VERSION ""

NS_ :

BS_:

BU_: ECM Racecapture BCM EHPAS ABS SteeringWheel PMU

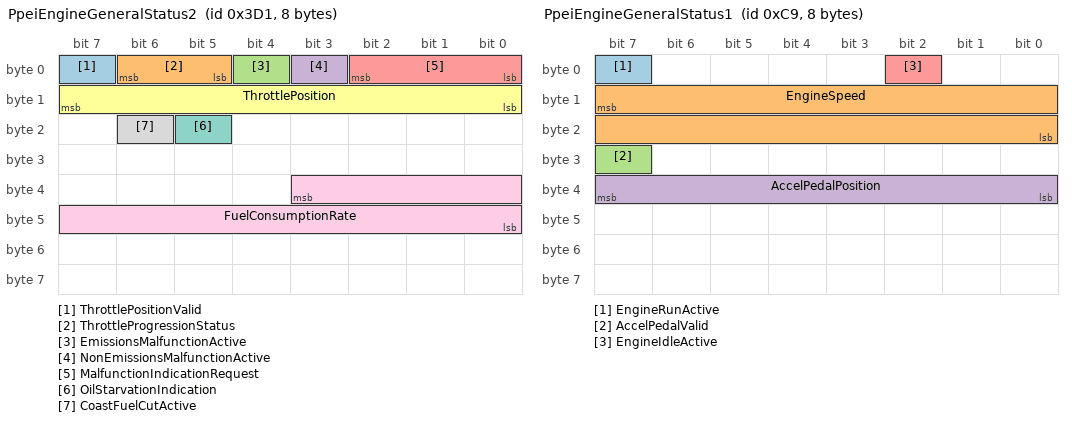
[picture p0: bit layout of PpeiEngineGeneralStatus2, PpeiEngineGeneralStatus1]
BO_ 977 PpeiEngineGeneralStatus2: 8 ECM
 SG_ ThrottlePositionValid : 7|1@1+ (1,0) [0|0] "flag" Vector__XXX
 SG_ ThrottleProgressionStatus : 6|2@0+ (1,0) [0|0] ""  BCM
 SG_ EmissionsMalfunctionActive : 4|1@1+ (1,0) [0|0] "flag" Vector__XXX
 SG_ NonEmissionsMalfunctionActive : 3|1@1+ (1,0) [0|0] "flag" Vector__XXX
 SG_ MalfunctionIndicationRequest : 2|3@0+ (1,0) [0|0] "" Vector__XXX
 SG_ ThrottlePosition : 15|8@0+ (0.39215686274,0) [0|100] "%" Vector__XXX
 SG_ OilStarvationIndication : 21|1@1+ (1,0) [0|0] "flag"  Racecapture
 SG_ CoastFuelCutActive : 22|1@1+ (1,0) [0|0] "flag" Vector__XXX
 SG_ FuelConsumptionRate : 35|12@0+ (0.025,0) [0|102.375] "L/h"  Racecapture

BO_ 201 PpeiEngineGeneralStatus1: 8 ECM
 SG_ EngineRunActive : 7|1@0+ (1,0) [0|0] "flag"  Racecapture,BCM
 SG_ EngineSpeed : 15|16@0+ (0.25,0) [0|16383.8] "rpm"  Racecapture,BCM
 SG_ AccelPedalValid : 31|1@0+ (1,0) [0|0] "flag" Vector__XXX
 SG_ AccelPedalPosition : 39|8@0+ (0.39215686274,0) [0|100] "%"  BCM,Racecapture
 SG_ EngineIdleActive : 2|1@0+ (1,0) [0|0] "" Vector__XXX

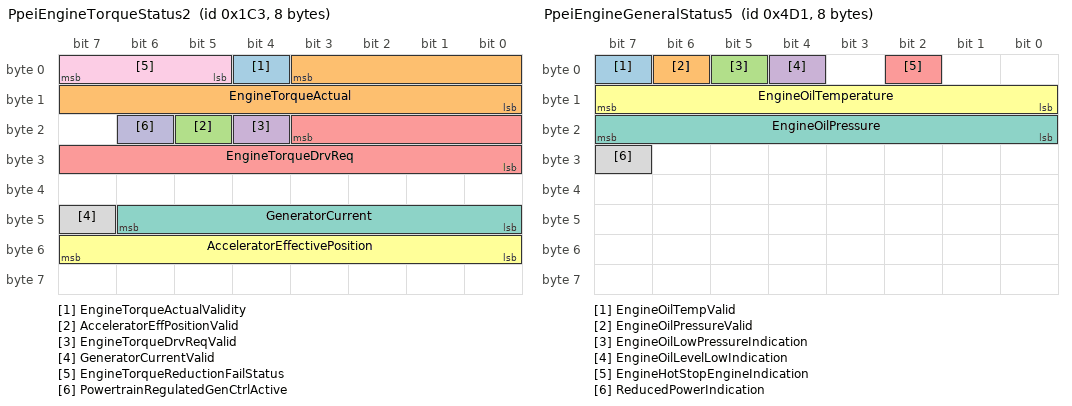
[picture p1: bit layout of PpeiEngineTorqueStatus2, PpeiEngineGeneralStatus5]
BO_ 451 PpeiEngineTorqueStatus2: 8 ECM
 SG_ EngineTorqueActualValidity : 4|1@0+ (1,0) [0|0] "flag" Vector__XXX
 SG_ EngineTorqueActual : 3|12@0+ (0.5,-848) [-848|1199.5] "Nm"  Racecapture
 SG_ AcceleratorEffPositionValid : 21|1@0+ (1,0) [0|0] "flag" Vector__XXX
 SG_ EngineTorqueDrvReqValid : 20|1@0+ (1,0) [0|0] "flag" Vector__XXX
 SG_ EngineTorqueDrvReq : 19|12@0+ (0.5,-848) [-848|1199.5] "Nm" Vector__XXX
 SG_ AcceleratorEffectivePosition : 55|8@0+ (0.39215686274,0) [0|100] "%" Vector__XXX
 SG_ GeneratorCurrent : 46|7@0+ (1,0) [0|127] "A" Vector__XXX
 SG_ GeneratorCurrentValid : 47|1@0+ (1,0) [0|0] "flag" Vector__XXX
 SG_ EngineTorqueReductionFailStatus : 7|3@0+ (1,0) [0|0] "enum" Vector__XXX
 SG_ PowertrainRegulatedGenCtrlActive : 22|1@0+ (1,0) [0|0] "flag" Vector__XXX

BO_ 1233 PpeiEngineGeneralStatus5: 8 ECM
 SG_ EngineOilTempValid : 7|1@1+ (1,0) [0|0] "flag" Vector__XXX
 SG_ EngineOilPressureValid : 6|1@1+ (1,0) [0|0] "flag" Vector__XXX
 SG_ EngineOilLowPressureIndication : 5|1@1+ (1,0) [0|0] "flag"  Racecapture
 SG_ EngineOilLevelLowIndication : 4|1@1+ (1,0) [0|0] "flag"  Racecapture
 SG_ EngineHotStopEngineIndication : 2|1@1+ (1,0) [0|0] "flag" Vector__XXX
 SG_ EngineOilTemperature : 15|8@0+ (1,-40) [-40|215] "deg C"  Racecapture
 SG_ EngineOilPressure : 23|8@0+ (4,0) [0|1020] "kPa"  Racecapture
 SG_ ReducedPowerIndication : 31|1@1+ (1,0) [0|0] "flag" Vector__XXX

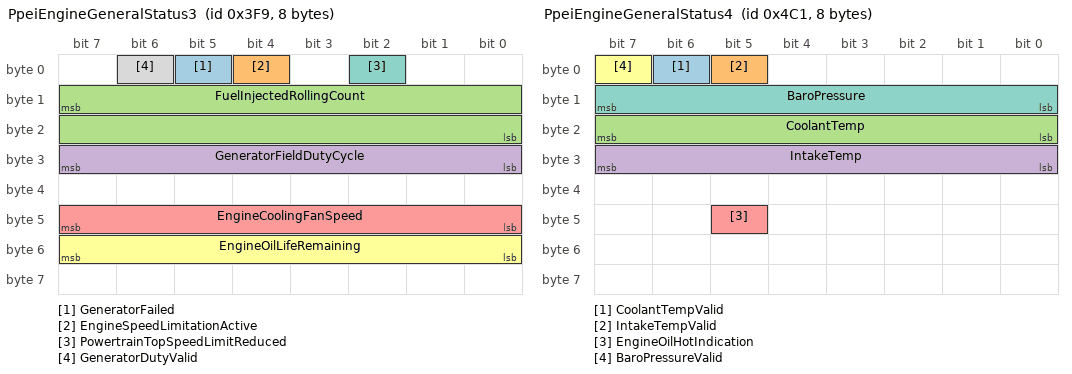
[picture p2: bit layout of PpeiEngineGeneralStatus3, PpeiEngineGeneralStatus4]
BO_ 1017 PpeiEngineGeneralStatus3: 8 ECM
 SG_ GeneratorFailed : 5|1@1+ (1,0) [0|0] "flag"  Racecapture
 SG_ EngineSpeedLimitationActive : 4|1@1+ (1,0) [0|0] "flag"  Racecapture
 SG_ FuelInjectedRollingCount : 15|16@0+ (3.0517578125e-05,0) [0|2] "liter"  BCM
 SG_ GeneratorFieldDutyCycle : 31|8@0+ (0.39215686274,0) [0|100] "%" Vector__XXX
 SG_ EngineCoolingFanSpeed : 47|8@0+ (0.39215686274,0) [0|100] "%" Vector__XXX
 SG_ EngineOilLifeRemaining : 55|8@0+ (0.39215686274,0) [0|100] "%" Vector__XXX
 SG_ PowertrainTopSpeedLimitReduced : 2|1@0+ (1,0) [0|0] "flag" Vector__XXX
 SG_ GeneratorDutyValid : 6|1@0+ (1,0) [0|0] "flag" Vector__XXX

BO_ 1019 PpeiEngineFuelStatus: 8 ECM
 SG_ EngineFuelControlState : 1|2@0+ (1,0) [0|0] ""  Racecapture
 SG_ FuelAlcoholComposition : 15|8@0+ (0.39215686274,0) [0|100] "%"  Racecapture

BO_ 1217 PpeiEngineGeneralStatus4: 8 ECM
 SG_ CoolantTempValid : 6|1@1+ (1,0) [0|0] "flag" Vector__XXX
 SG_ IntakeTempValid : 5|1@1+ (1,0) [0|0] "flag" Vector__XXX
 SG_ CoolantTemp : 23|8@0+ (1,-40) [-40|215] "deg C"  Racecapture
 SG_ IntakeTemp : 31|8@0+ (1,-40) [-40|215] "deg C"  Racecapture
 SG_ EngineOilHotIndication : 45|1@1+ (1,0) [0|0] "flag"  Racecapture
 SG_ BaroPressureValid : 7|1@1+ (1,0) [0|0] "flag" Vector__XXX
 SG_ BaroPressure : 15|8@0+ (0.5,0) [0|127.5] "kPa" Vector__XXX

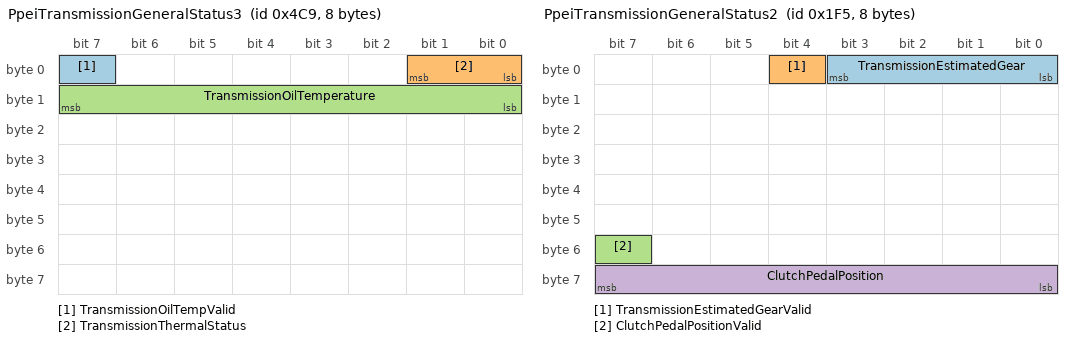
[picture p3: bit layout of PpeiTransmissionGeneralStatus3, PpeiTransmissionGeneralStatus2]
BO_ 1225 PpeiTransmissionGeneralStatus3: 8 ECM
 SG_ TransmissionOilTempValid : 7|1@1+ (1,0) [0|0] "flag" Vector__XXX
 SG_ TransmissionThermalStatus : 1|2@0+ (1,0) [0|0] "" Vector__XXX
 SG_ TransmissionOilTemperature : 15|8@0+ (1,-40) [-40|215] "deg C"  Racecapture

BO_ 495 PpeiFuelSystemRequest2: 8 ECM
 SG_ MassAirFlow : 7|16@0+ (0.01,0) [0|655.35] "g/s"  Racecapture

BO_ 501 PpeiTransmissionGeneralStatus2: 8 ECM
 SG_ TransmissionEstimatedGear : 0|4@1+ (1,0) [0|0] ""  Racecapture
 SG_ TransmissionEstimatedGearValid : 4|1@1+ (1,0) [0|0] "flag" Vector__XXX
 SG_ ClutchPedalPositionValid : 55|1@1+ (1,0) [0|0] "flag" Vector__XXX
 SG_ ClutchPedalPosition : 63|8@0+ (0.39215686274,0) [0|100] "%"  Racecapture

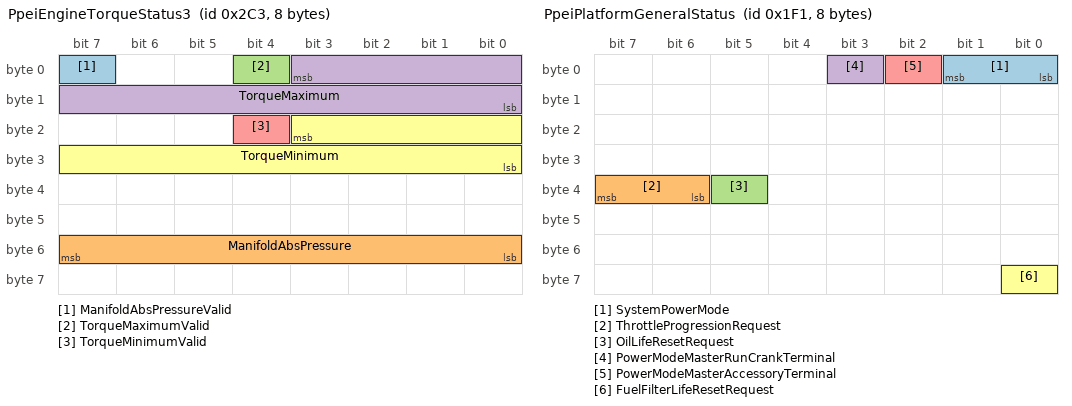
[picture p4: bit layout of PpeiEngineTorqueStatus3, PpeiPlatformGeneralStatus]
BO_ 707 PpeiEngineTorqueStatus3: 8 ECM
 SG_ ManifoldAbsPressureValid : 7|1@1+ (1,0) [0|0] "flag" Vector__XXX
 SG_ ManifoldAbsPressure : 55|8@0+ (0.5,0) [0|127.5] "kPa"  Racecapture
 SG_ TorqueMaximumValid : 4|1@1+ (1,0) [0|0] "flag" Vector__XXX
 SG_ TorqueMaximum : 3|12@0+ (0.5,-848) [-848|1199.5] "Nm" Vector__XXX
 SG_ TorqueMinimumValid : 20|1@0+ (1,0) [0|0] "flag" Vector__XXX
 SG_ TorqueMinimum : 19|12@0+ (0.5,-848) [-848|1199.5] "Nm" Vector__XXX

BO_ 1001 PpeiVehicleSpeedAndDistance: 8 ECM
 SG_ VehicleSpeedDrivenValid : 7|1@1+ (1,0) [0|0] "" Vector__XXX
 SG_ VehicleSpeedDriven : 6|15@0+ (0.015625,0) [0|511.46] "km/h"  Racecapture

BO_ 497 PpeiPlatformGeneralStatus: 8 BCM
 SG_ SystemPowerMode : 1|2@0+ (1,0) [0|0] ""  ECM
 SG_ ThrottleProgressionRequest : 39|2@0+ (1,0) [0|0] ""  ECM
 SG_ OilLifeResetRequest : 37|1@0+ (1,0) [0|0] ""  ECM
 SG_ PowerModeMasterRunCrankTerminal : 3|1@0+ (1,0) [0|0] "" Vector__XXX
 SG_ PowerModeMasterAccessoryTerminal : 2|1@0+ (1,0) [0|0] "" Vector__XXX
 SG_ FuelFilterLifeResetRequest : 56|1@0+ (1,0) [0|0] "" Vector__XXX

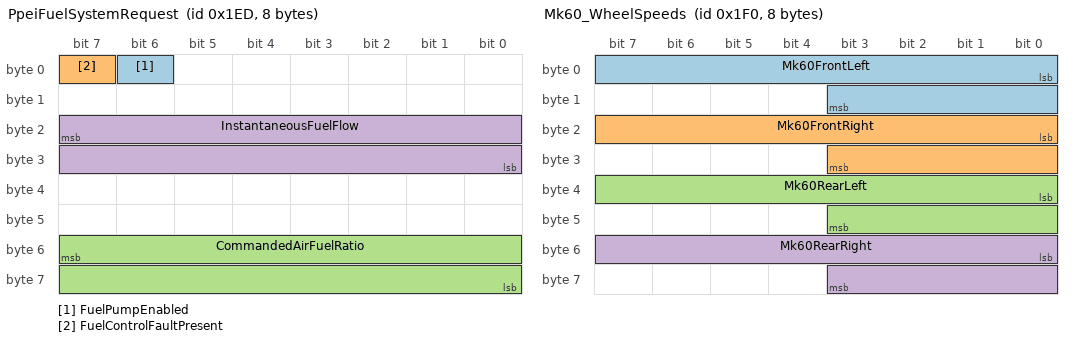
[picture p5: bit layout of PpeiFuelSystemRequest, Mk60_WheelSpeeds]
BO_ 493 PpeiFuelSystemRequest: 8 ECM
 SG_ FuelPumpEnabled : 6|1@1+ (1,0) [0|0] "flag"  BCM
 SG_ FuelControlFaultPresent : 7|1@1+ (1,0) [0|0] "flag" Vector__XXX
 SG_ CommandedAirFuelRatio : 55|16@0+ (0.00048828125,0) [0|32] "ratio"  ECM
 SG_ InstantaneousFuelFlow : 23|16@0+ (0.0009765625,0) [0|64] "g/s"  ECM

BO_ 2598373676 VolvoPowerSteeringIgnitionOn: 8 BCM
 SG_ EhpasIgnitionRollCount : 8|8@1+ (1,0) [0|0] ""  EHPAS

BO_ 2602565634 VolvoPowerSteeringAlive: 8 EHPAS
 SG_ VolvoEhpasAlive : 0|64@1+ (1,0) [0|0] "" Vector__XXX

BO_ 2182103350 VolvoPowerSteeringSpeed: 8 BCM
 SG_ EhpasVehicleSpeed : 55|16@0+ (0.01,0) [0|0] "km/h"  EHPAS

BO_ 496 Mk60_WheelSpeeds: 8 ABS
 SG_ Mk60FrontLeft : 0|12@1+ (0.03125,-0.5) [0|0] "km/h" Vector__XXX
 SG_ Mk60FrontRight : 16|12@1+ (0.03125,-0.5) [0|0] "km/h" Vector__XXX
 SG_ Mk60RearLeft : 32|12@1+ (0.03125,-0.5) [0|0] "km/h" Vector__XXX
 SG_ Mk60RearRight : 48|12@1+ (0.03125,-0.5) [0|0] "km/h" Vector__XXX

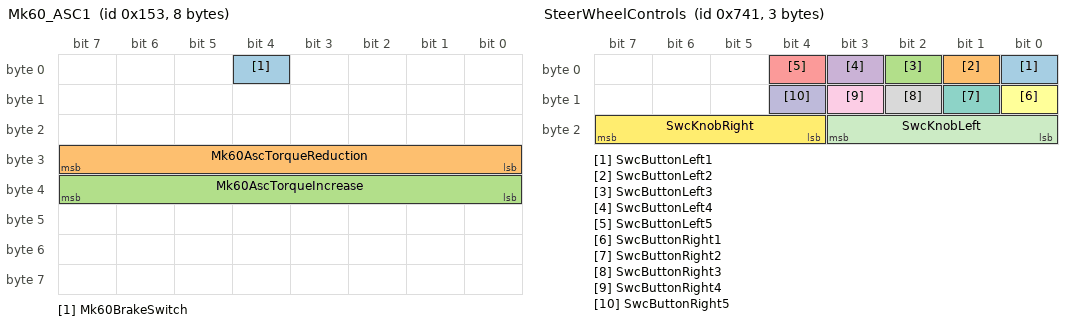
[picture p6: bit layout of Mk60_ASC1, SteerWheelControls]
BO_ 339 Mk60_ASC1: 8 ABS
 SG_ Mk60BrakeSwitch : 4|1@1+ (1,0) [0|0] "flag"  BCM
 SG_ Mk60AscTorqueReduction : 24|8@1+ (0.390625,0) [0|100] "%"  BCM
 SG_ Mk60AscTorqueIncrease : 32|8@1+ (0.390625,0) [0|100] "%"  BCM

BO_ 809 Mk60_DME2: 8 BCM
 SG_ Mk60Wakeup1 : 0|64@1+ (1,0) [0|0] ""  ABS

BO_ 1552 Mk60_ICL1: 8 BCM
 SG_ Mk60Wakeup2 : 0|64@1+ (1,0) [0|0] ""  ABS

BO_ 1857 SteerWheelControls: 3 SteeringWheel
 SG_ SwcButtonLeft1 : 0|1@1+ (1,0) [0|0] ""  BCM
 SG_ SwcButtonLeft2 : 1|1@1+ (1,0) [0|0] ""  BCM
 SG_ SwcButtonLeft3 : 2|1@1+ (1,0) [0|0] ""  BCM
 SG_ SwcButtonLeft4 : 3|1@1+ (1,0) [0|0] ""  BCM
 SG_ SwcButtonLeft5 : 4|1@1+ (1,0) [0|0] ""  BCM
 SG_ SwcButtonRight1 : 8|1@1+ (1,0) [0|0] ""  BCM
 SG_ SwcButtonRight2 : 9|1@1+ (1,0) [0|0] ""  BCM
 SG_ SwcButtonRight3 : 10|1@1+ (1,0) [0|0] ""  BCM
 SG_ SwcButtonRight4 : 11|1@1+ (1,0) [0|0] ""  BCM
 SG_ SwcButtonRight5 : 12|1@1+ (1,0) [0|0] ""  BCM
 SG_ SwcKnobLeft : 16|4@1+ (1,0) [0|0] ""  BCM
 SG_ SwcKnobRight : 20|4@1+ (1,0) [0|0] ""  BCM

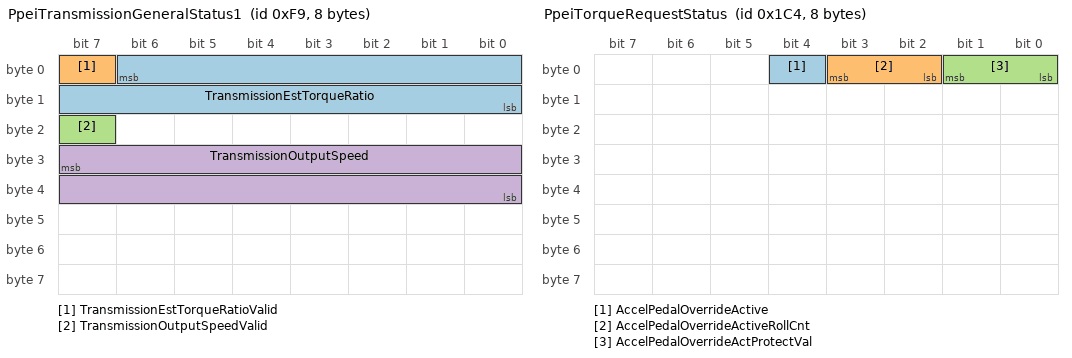
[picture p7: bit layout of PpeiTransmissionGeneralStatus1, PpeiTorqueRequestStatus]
BO_ 249 PpeiTransmissionGeneralStatus1: 8 ECM
 SG_ TransmissionEstTorqueRatio : 6|15@0- (0.00390625,0) [-64|63.996093] "ratio" Vector__XXX
 SG_ TransmissionEstTorqueRatioValid : 7|1@0+ (1,0) [0|0] "" Vector__XXX
 SG_ TransmissionOutputSpeedValid : 23|1@0+ (1,0) [0|0] "flag" Vector__XXX
 SG_ TransmissionOutputSpeed : 31|16@0+ (0.25,0) [0|16383.75] "rpm" Vector__XXX

BO_ 417 PteiEngineGeneralStatus: 8 ECM

BO_ 452 PpeiTorqueRequestStatus: 8 ECM
 SG_ AccelPedalOverrideActive : 4|1@0+ (1,0) [0|0] "" Vector__XXX
 SG_ AccelPedalOverrideActiveRollCnt : 3|2@0+ (1,0) [0|0] "" Vector__XXX
 SG_ AccelPedalOverrideActProtectVal : 1|2@0+ (1,0) [0|0] "" Vector__XXX

BO_ 961 PpeiPowertrainImmobilizerData: 8 ECM

BO_ 1265 PpeiPowertrainConfigurationData: 8 ECM

BO_ 1267 PpeiPowertrainConfigurationData2: 8 ECM

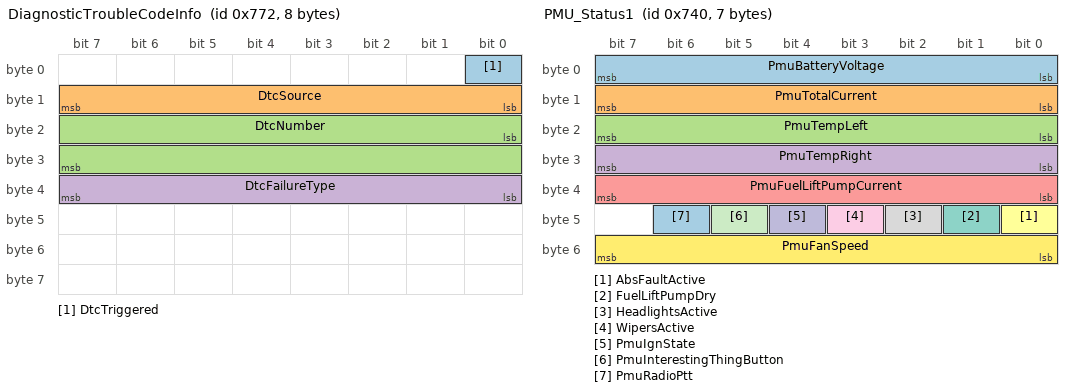
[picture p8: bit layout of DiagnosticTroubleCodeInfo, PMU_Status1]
BO_ 1906 DiagnosticTroubleCodeInfo: 8 ECM
 SG_ DtcTriggered : 0|1@1+ (1,0) [0|0] "" Vector__XXX
 SG_ DtcSource : 8|8@1+ (1,0) [0|0] "" Vector__XXX
 SG_ DtcNumber : 16|16@1+ (1,0) [0|0] "" Vector__XXX
 SG_ DtcFailureType : 32|8@1+ (1,0) [0|0] "" Vector__XXX

BO_ 1856 PMU_Status1: 7 PMU
 SG_ PmuBatteryVoltage : 0|8@1+ (0.1,0) [0|25.5] "V" Vector__XXX
 SG_ PmuTotalCurrent : 8|8@1+ (1,0) [0|255] "A" Vector__XXX
 SG_ PmuTempLeft : 16|8@1+ (1,0) [0|150] "C" Vector__XXX
 SG_ PmuTempRight : 24|8@1+ (1,0) [0|150] "C" Vector__XXX
 SG_ PmuFuelLiftPumpCurrent : 32|8@1+ (0.1,0) [0|25.5] "A" Vector__XXX
 SG_ AbsFaultActive : 40|1@1+ (1,0) [0|1] "flag" Vector__XXX
 SG_ FuelLiftPumpDry : 41|1@1+ (1,0) [0|1] "flag" Vector__XXX
 SG_ HeadlightsActive : 42|1@1+ (1,0) [0|1] "flag" Vector__XXX
 SG_ WipersActive : 43|1@1+ (1,0) [0|1] "flag" Vector__XXX
 SG_ PmuIgnState : 44|1@1+ (1,0) [0|1] "flag" Vector__XXX
 SG_ PmuInterestingThingButton : 45|1@1+ (1,0) [0|1] "flag" Vector__XXX
 SG_ PmuFanSpeed : 48|8@1+ (1,0) [0|100] "%" Vector__XXX
 SG_ PmuRadioPtt : 46|1@1+ (1,0) [0|0] "flag" Vector__XXX

BO_ 1009 PpeiPlatformEngineCntrlRequests: 8 BCM
 SG_ GeneratorRegulatorDutyRequest : 15|8@0+ (0.392156863,0) [0|0] "%" Vector__XXX
 SG_ PlatformIdleBoostRequest : 25|2@0+ (1,0) [0|0] "" Vector__XXX

BO_ 100 RacecaptureGpsPos: 8 Racecapture
 SG_ RC_Latitude : 0|32@1- (1e-07,0) [-90|90] "deg" Vector__XXX
 SG_ RC_Longitude : 32|32@1- (1e-07,0) [-180|180] "deg" Vector__XXX

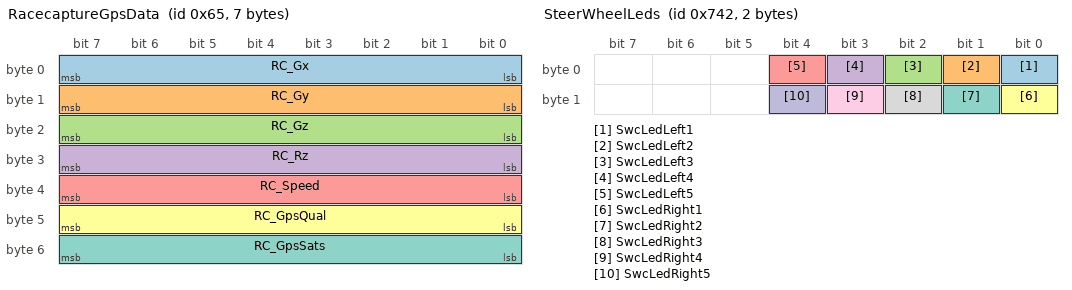
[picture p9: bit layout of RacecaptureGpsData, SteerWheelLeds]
BO_ 101 RacecaptureGpsData: 7 Racecapture
 SG_ RC_Gx : 0|8@1- (0.02,0) [0|0] "" Vector__XXX
 SG_ RC_Gy : 8|8@1- (0.02,0) [0|0] "" Vector__XXX
 SG_ RC_Gz : 16|8@1- (0.02,0) [0|0] "" Vector__XXX
 SG_ RC_Rz : 24|8@1- (0.02,0) [0|0] "" Vector__XXX
 SG_ RC_Speed : 32|8@1+ (1,0) [0|0] "" Vector__XXX
 SG_ RC_GpsQual : 40|8@1+ (1,0) [0|0] "" Vector__XXX
 SG_ RC_GpsSats : 48|8@1+ (1,0) [0|0] "" Vector__XXX

BO_ 1858 SteerWheelLeds: 2 PMU
 SG_ SwcLedLeft1 : 0|1@1+ (1,0) [0|0] "" Vector__XXX
 SG_ SwcLedLeft2 : 1|1@1+ (1,0) [0|0] "" Vector__XXX
 SG_ SwcLedLeft3 : 2|1@1+ (1,0) [0|0] "" Vector__XXX
 SG_ SwcLedLeft4 : 3|1@1+ (1,0) [0|0] "" Vector__XXX
 SG_ SwcLedLeft5 : 4|1@1+ (1,0) [0|0] "" Vector__XXX
 SG_ SwcLedRight1 : 8|1@1+ (1,0) [0|0] "" Vector__XXX
 SG_ SwcLedRight2 : 9|1@1+ (1,0) [0|0] "" Vector__XXX
 SG_ SwcLedRight3 : 10|1@1+ (1,0) [0|0] "" Vector__XXX
 SG_ SwcLedRight4 : 11|1@1+ (1,0) [0|0] "" Vector__XXX
 SG_ SwcLedRight5 : 12|1@1+ (1,0) [0|0] "" Vector__XXX

BO_ 499 Mk60_ASC3: 8 ABS

BO_ 102 Unknown_x066: 2 Vector__XXX

BO_ 190 GMLAN_PossibleAccelPos: 8 ECM

BO_ 419 GMLAN_Unknown1: 1 ECM

BO_ 426 GMLAN_Unknown2: 8 ECM

BO_ 479 GMLAN_Unknown3: 3 ECM

BO_ 487 GMLAN_Unknown4: 8 ECM

BO_ 500 GMLAN_Unknown5: 6 ECM

BO_ 647 GMLAN_Unknown6: 4 ECM

BO_ 723 GMLAN_Unknown7: 2 ECM

BO_ 985 GMLAN_Unknown8: 5 ECM

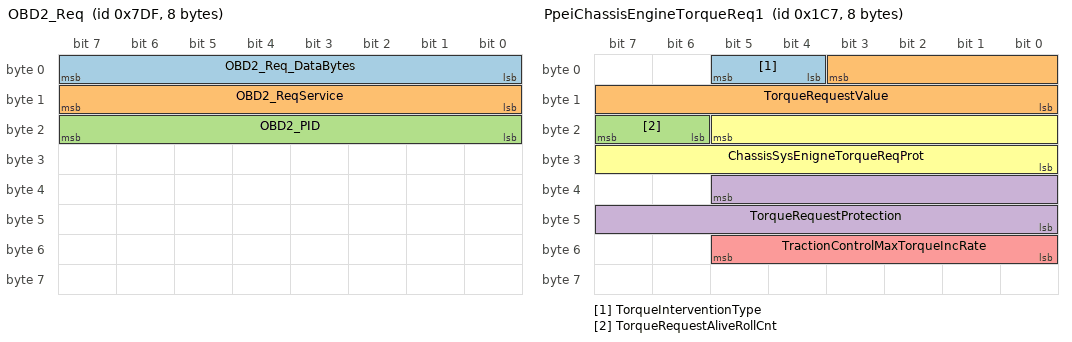
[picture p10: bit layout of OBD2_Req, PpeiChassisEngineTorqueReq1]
BO_ 2015 OBD2_Req: 8 Vector__XXX
 SG_ OBD2_Req_DataBytes : 0|8@1+ (1,0) [0|0] "" Vector__XXX
 SG_ OBD2_ReqService : 8|8@1+ (1,0) [0|0] "" Vector__XXX
 SG_ OBD2_PID : 16|8@1+ (1,0) [0|0] "" Vector__XXX

BO_ 2024 OBD2_Resp: 8 ECM
 SG_ OBD2_Resp_DataBytes : 0|8@1+ (1,0) [0|0] "" Vector__XXX
 SG_ OBD2_Resp_Service : 8|8@1+ (1,-64) [0|0] "" Vector__XXX
 SG_ OBD2_Resp_Pid M : 16|8@1+ (1,0) [0|0] "" Vector__XXX
 SG_ OBD2_STFT1 m6 : 24|8@1+ (0.78125,-100) [0|0] "" Vector__XXX
 SG_ OBD2_STFT2 m8 : 24|8@1+ (0.78125,-100) [0|0] "" Vector__XXX

BO_ 455 PpeiChassisEngineTorqueReq1: 8 Vector__XXX
 SG_ TorqueInterventionType : 4|2@1+ (1,0) [0|0] "enum" Vector__XXX
 SG_ TorqueRequestValue : 3|12@0+ (0.5,-848) [-848|1199.5] "Nm" Vector__XXX
 SG_ TorqueRequestAliveRollCnt : 23|2@0+ (1,0) [0|0] "" Vector__XXX
 SG_ TorqueRequestProtection : 37|14@0+ (1,0) [0|0] "" Vector__XXX
 SG_ TractionControlMaxTorqueIncRate : 53|6@0+ (16,0) [0|1008] "Nm/s" Vector__XXX
 SG_ ChassisSysEnigneTorqueReqProt : 21|14@0+ (1,0) [0|0] "" Vector__XXX

BO_ 489 PpeiChassisGeneralStatus1: 8 Vector__XXX
 SG_ VehicleStabilityEnhLatAccel : 3|12@0- (0.015625,0) [-32|31.9844] "m/s2" Vector__XXX
 SG_ VehicleStabilityEnhLatAccelValid : 4|1@0+ (1,0) [0|0] "flag" Vector__XXX
 SG_ TransBrakeSystemClutchRelReq : 5|1@0+ (1,0) [0|0] "flag" Vector__XXX
 SG_ BrakePedalDriverAppliedPress : 6|1@0+ (1,0) [0|0] "flag" Vector__XXX
 SG_ BrakePedalDriverAppPressValid : 7|1@0+ (1,0) [0|0] "flag" Vector__XXX
 SG_ BrakeSysTransGearReqType : 21|2@0+ (1,0) [0|0] "enum" Vector__XXX
 SG_ BrakeSysTransGearReq : 19|4@0+ (1,0) [0|0] "" Vector__XXX
 SG_ AdaptiveCruiseBrakeActive : 31|1@0+ (1,0) [0|0] "flag" Vector__XXX
 SG_ AntilockBrakeActive : 30|1@0+ (1,0) [0|0] "flag" Vector__XXX
 SG_ AntilockBrakeFailed : 29|1@0+ (1,0) [0|0] "flag" Vector__XXX
 SG_ TractionControlSystemActive : 28|1@0+ (1,0) [0|0] "flag" Vector__XXX
 SG_ TractionControlSystemEnabled : 27|1@0+ (1,0) [0|0] "flag" Vector__XXX
 SG_ TractionControlSystemDriverInten : 26|1@0+ (1,0) [0|0] "flag" Vector__XXX
 SG_ VehicleStabilitySystemActive : 24|1@0+ (1,0) [0|0] "flag" Vector__XXX
 SG_ VehicleDynamicsCtrlSysStatus : 39|3@0+ (1,0) [0|0] "enum" Vector__XXX
 SG_ VehicleDynamicsYawRateValid : 36|1@0+ (1,0) [0|0] "flag" Vector__XXX
 SG_ VehicleDynamicsYawRate : 35|12@0- (0.0625,0) [-128|127.938] "deg/s" Vector__XXX
 SG_ DriverIndependentBrakeApply : 55|1@0+ (1,0) [0|0] "flag" Vector__XXX
 SG_ VehicleDynOverUnderSteerValid : 50|1@0+ (1,0) [0|0] "flag" Vector__XXX
 SG_ VehicleDynOverUnderSteer : 49|10@0- (0.5,0) [-256|255.5] "%" Vector__XXX

BO_ 1257 PpeiPlatofrmConfigurationData: 8 Vector__XXX
 SG_ AntilockBrakeSystemPresent : 7|1@1+ (1,0) [0|0] "" Vector__XXX
 SG_ TractionControlSystemPresent : 6|1@1+ (1,0) [0|0] "" Vector__XXX

CM_ BU_ ECM "GM E82 ECM";
CM_ BU_ EHPAS "Volvo EHPAS Pump";
CM_ BU_ ABS "Teves MK60";
CM_ BO_ 977 "10hz";
CM_ SG_ 977 ThrottlePosition "True throttle plate position";
CM_ BO_ 201 "80hz";
CM_ BO_ 451 "40hz";
CM_ BO_ 1233 "2hz";
CM_ BO_ 1017 "4hz";
CM_ BO_ 1019 "4hz";
CM_ BO_ 1217 "2hz";
CM_ BO_ 1225 "2hz";
CM_ BO_ 495 "80hz";
CM_ BO_ 501 "40hz";
CM_ BO_ 707 "20hz";
CM_ BO_ 1001 "10hz";
CM_ BO_ 497 "10hz";
CM_ BO_ 493 "80hz";
CM_ BO_ 2598373676 "Send at ~2hz";
CM_ BO_ 2182103350 "Send at ~70hz";
CM_ SG_ 2182103350 EhpasVehicleSpeed "factor is a guess";
CM_ BO_ 496 "140hz";
CM_ BO_ 339 "140hz";
CM_ BO_ 809 "1hz";
CM_ BO_ 1552 "1hz";
CM_ BO_ 1857 "20hz";
CM_ BO_ 249 "80hz";
CM_ BO_ 417 "40hz";
CM_ BO_ 452 "40hz";
CM_ BO_ 961 "10hz";
CM_ BO_ 1265 "1hz";
CM_ BO_ 1267 "1hz";
CM_ BO_ 1906 "1hz";
CM_ BO_ 1856 "10hz";
CM_ BO_ 1009 "4hz";
CM_ BO_ 100 "25hz";
CM_ BO_ 101 "25hz";
CM_ BO_ 1858 "20hz";
CM_ BO_ 499 "140hz";
CM_ BO_ 419 "40hz";
CM_ BO_ 426 "40hz";
CM_ BO_ 479 "40hz";
CM_ BO_ 487 "80hz";
CM_ BO_ 500 "40hz";
CM_ BO_ 647 "40hz";
CM_ BO_ 723 "20hz";
CM_ BO_ 985 "10hz";
CM_ BO_ 455 "50hz";
CM_ BO_ 489 "50hz";
CM_ BO_ 1257 "1hz";
VAL_ 977 ThrottleProgressionStatus 0 "MapA" 1 "MapB" 2 "MapC" 3 "EcmSelected" ;
VAL_ 977 MalfunctionIndicationRequest 0 "ContinuousIndication" 1 "NoIndication" 2 "Flashing1hz" 3 "Flashing2hz" 4 "Flashing0_5hz" ;
VAL_ 451 EngineTorqueReductionFailStatus 0 "OK" 1 "TemporarilyFailed" 2 "PermanentlyFailed" 3 "Limited" 4 "CommFailed" ;
VAL_ 1019 EngineFuelControlState 0 "OpenLoop" 1 "NonStoichClosedLoop" 2 "StoichClosedLoop" ;
VAL_ 1225 TransmissionThermalStatus 0 "Normal" 1 "CountermeasuresActive" 2 "DriverInterventionRequest" ;
VAL_ 501 TransmissionEstimatedGear 1 "Gear1" 2 "Gear2" 3 "Gear3" 4 "Gear4" 5 "Gear5" 6 "Gear6" 7 "Gear7" 8 "Gear8" 9 "CvtForward" 10 "Neutral" 11 "Reverse" 12 "Park" 0 "NotSupported" ;
VAL_ 497 SystemPowerMode 0 "Off" 1 "Accessory" 2 "Run" 3 "CrankRequest" ;
VAL_ 497 ThrottleProgressionRequest 0 "MapA" 1 "MapB" 2 "MapC" ;
VAL_ 1009 PlatformIdleBoostRequest 1 "BoostLevel1" 2 "BoostLevel2" 3 "BoostLevel3" 0 "NoBoost" ;
VAL_ 455 TorqueInterventionType 0 "NoIntervention" 1 "ReduceTorque" 2 "IncreaseTorque" ;
VAL_ 489 BrakeSysTransGearReqType 0 "NoAction" 1 "MaxGearRequest" 2 "MinGearRequest" 3 "HoldGear" ;
VAL_ 489 VehicleDynamicsCtrlSysStatus 1 "NormalOperation" ;
